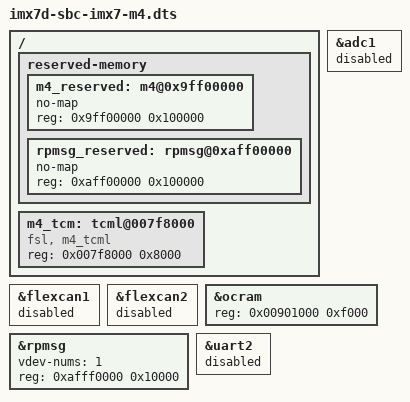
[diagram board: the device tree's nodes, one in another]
#include "imx7d-sbc-imx7.dts"

/ {
	reserved-memory {
		#address-cells = <1>;
		#size-cells = <1>;
		ranges;

		m4_reserved: m4@0x9ff00000 {
			no-map;
			reg = <0x9ff00000 0x100000>;
		};

		rpmsg_reserved: rpmsg@0xaff00000 {
			no-map;
			reg = <0xaff00000 0x100000>;
		};
	};

	m4_tcm: tcml@007f8000 {
		compatible = "fsl, m4_tcml";
		reg = <0x007f8000 0x8000>;
	};
};

&adc1 {
	status = "disabled";
};

&flexcan1 {
	status = "disabled";
};

&flexcan2 {
	status = "disabled";
};

&ocram {
	reg = <0x00901000 0xf000>;
};

&rpmsg {
	vdev-nums = <1>;
	reg = <0xafff0000 0x10000>;
	status = "okay";
};

&uart2 {
	status = "disabled";
};

